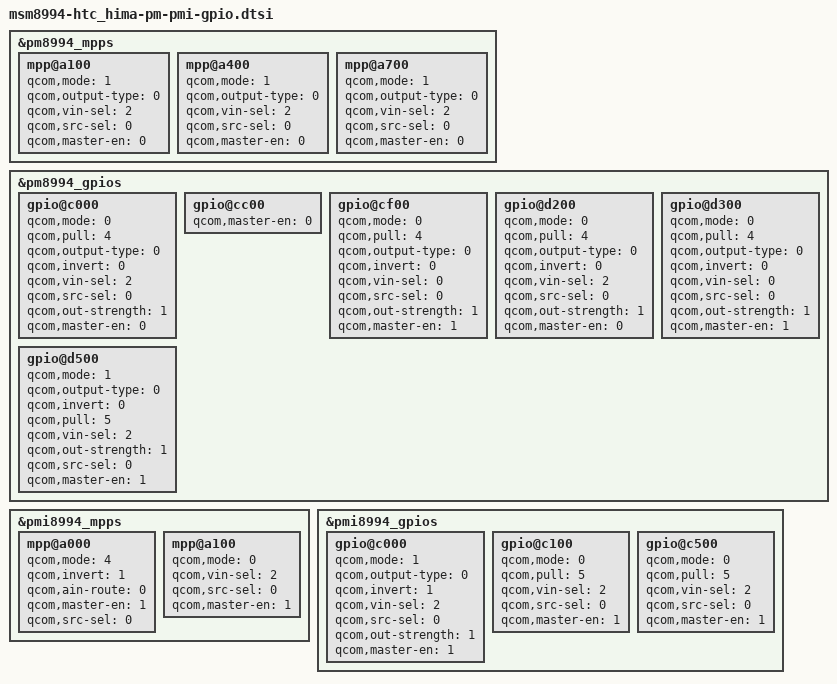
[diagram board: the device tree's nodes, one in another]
/* Copyright (c) 2014, The Linux Foundation. All rights reserved.
 *
 * This program is free software; you can redistribute it and/or modify
 * it under the terms of the GNU General Public License version 2 and
 * only version 2 as published by the Free Software Foundation.
 *
 * This program is distributed in the hope that it will be useful,
 * but WITHOUT ANY WARRANTY; without even the implied warranty of
 * MERCHANTABILITY or FITNESS FOR A PARTICULAR PURPOSE.  See the
 * GNU General Public License for more details.
 */

/* PM8994 MPP Init Settings */
&pm8994_mpps {
	mpp@a100 { /* MPP 2 */
		qcom,mode = <1>;		/* Digital output */
		qcom,output-type = <0>;		/* CMOS logic */
		qcom,vin-sel = <2>;		/* S4 1.8V */
		qcom,src-sel = <0>;		/* Constant */
		qcom,master-en = <0>;		/* Disable GPIO */
		status = "okay";
	};

	mpp@a400 { /* MPP 5 */
		qcom,mode = <1>;		/* Digital output */
		qcom,output-type = <0>;		/* CMOS logic */
		qcom,vin-sel = <2>;		/* S4 1.8V */
		qcom,src-sel = <0>;		/* Constant */
		qcom,master-en = <0>;		/* Disable GPIO */
		status = "okay";
	};

	mpp@a700 { /* MPP 8 */
		qcom,mode = <1>;		/* Digital output */
		qcom,output-type = <0>;		/* CMOS logic */
		qcom,vin-sel = <2>;		/* S4 1.8V */
		qcom,src-sel = <0>;		/* Constant */
		qcom,master-en = <0>;		/* Disable GPIO */
		status = "okay";
	};
};

/* PM8994 GPIO Init Settings */
&pm8994_gpios {
	gpio@c000 { /* GPIO 1 */
		qcom,mode = <0>;                /* Digital in */
		qcom,pull = <4>;                /* PULL DN */
		qcom,output-type = <0>;         /* CMOS logic */
		qcom,invert = <0>;              /* No Inversion */
		qcom,vin-sel = <2>;             /* Logical 1 voltage value 1.8v */
		qcom,src-sel = <0>;             /* Constant */
		qcom,out-strength = <1>;        /* Low drive strength */
		qcom,master-en = <0>;           /* Disable GPIO */
		status = "okay";
	};

	gpio@cc00 { /* GPIO 13 */
		qcom,master-en = <0>;
	};

	gpio@cf00 { /* GPIO 16 */
		qcom,mode = <0>;                /* Digital in */
		qcom,pull = <4>;                /* PULL DN */
		qcom,output-type = <0>;         /* CMOS logic */
		qcom,invert = <0>;              /* No Inversion */
		qcom,vin-sel = <0>;             /* Logical 1 voltage value 1.8v */
		qcom,src-sel = <0>;             /* Constant */
		qcom,out-strength = <1>;        /* Low drive strength */
		qcom,master-en = <1>;           /* Disable GPIO */
		status = "okay";
	};

	gpio@d200 { /* GPIO 19 */
		qcom,mode = <0>;                /* Digital in */
		qcom,pull = <4>;                /* PULL DN */
		qcom,output-type = <0>;         /* CMOS logic */
		qcom,invert = <0>;              /* No Inversion */
		qcom,vin-sel = <2>;             /* Logical 1 voltage value 1.8v */
		qcom,src-sel = <0>;             /* Constant */
		qcom,out-strength = <1>;        /* Low drive strength */
		qcom,master-en = <0>;           /* Disable GPIO */
		status = "okay";
	};

	gpio@d300 { /* GPIO 20 */
		qcom,mode = <0>;                /* Digital in */
		qcom,pull = <4>;                /* PULL DN */
		qcom,output-type = <0>;         /* CMOS logic */
		qcom,invert = <0>;              /* No Inversion */
		qcom,vin-sel = <0>;             /* Logical 1 voltage value 1.8v */
		qcom,src-sel = <0>;             /* Constant */
		qcom,out-strength = <1>;        /* Low drive strength */
		qcom,master-en = <1>;           /* Disable GPIO */
		status = "okay";
	};

	gpio@d500 { /* GPIO 22 */
		qcom,mode = <1>;        /* QPNP_PIN_MODE_DIG_OUT */
		qcom,output-type = <0>; /* QPNP_PIN_OUT_BUF_CMOS */
		qcom,invert = <0>;      /* Output low */
		qcom,pull = <5>;        /* QPNP_PIN_PULL_NO */
		qcom,vin-sel = <2>;
		qcom,out-strength = <1>;
		qcom,src-sel = <0>;
		qcom,master-en = <1>;
		status = "okay";
	};
};

/* PMI8994 MPP Init Settings */
&pmi8994_mpps {
	mpp@a000 { /* MPP 1 */
		qcom,mode = <4>;        /* AIN input */
		qcom,invert = <1>; /* Enable MPP */
		qcom,ain-route = <0>; /*AMUX*/
		qcom,master-en = <1>;
		qcom,src-sel = <0>; /* Funcion constant */
		status = "okay";
	};

	mpp@a100 { /* MPP 2 */
		qcom,mode = <0>;        /* QPNP_PIN_MODE_DIG_IN */
		qcom,vin-sel = <2>;     /* QPNP_PIN_VIN2 */
		qcom,src-sel = <0>;     /* QPNP_PIN_SEL_FUNC_CONSTANT */
		qcom,master-en = <1>;   /* Enable */
		status = "okay";
	};
};

/* PMI8994 GPIO Init Settings */
&pmi8994_gpios {
	gpio@c000 { /* GPIO 1 */
		qcom,mode = <1>;		/* Digital output */
		qcom,output-type = <0>;		/* CMOS logic */
		qcom,invert = <1>;		/* Output high */
		qcom,vin-sel = <2>;		/* QPNP_PIN_VIN2 */
		qcom,src-sel = <0>;		/* Constant */
		qcom,out-strength = <1>;	/* High drive strength */
		qcom,master-en = <1>;		/* Enable GPIO */
		status = "okay";
	};

	gpio@c100 { /* GPIO 2 */
		qcom,mode = <0>;                /* QPNP_PIN_MODE_DIG_IN */
		qcom,pull = <5>;                /* QPNP_PIN_NO_PULL*/
		qcom,vin-sel = <2>;             /* QPNP_PIN_VIN2 */
		qcom,src-sel = <0>;             /* GPIO */
		qcom,master-en = <1>;
		status = "okay";
	};

	gpio@c500 { /* GPIO 6 */
		qcom,mode = <0>;                /* QPNP_PIN_MODE_DIG_IN */
		qcom,pull = <5>;                /* QPNP_PIN_NO_PULL*/
		qcom,vin-sel = <2>;             /* QPNP_PIN_VIN2 */
		qcom,src-sel = <0>;             /* GPIO */
		qcom,master-en = <1>;
		status = "okay";
	};
};
